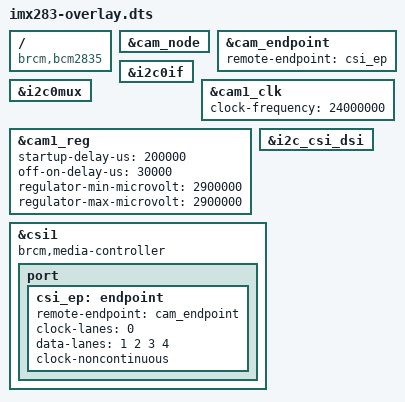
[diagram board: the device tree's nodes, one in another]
// SPDX-License-Identifier: GPL-2.0-only
// Definitions for IMX283 camera module on VC I2C bus
/dts-v1/;
/plugin/;

#include <dt-bindings/gpio/gpio.h>

/{
	compatible = "brcm,bcm2835";

	fragment@0 {
		target = <&i2c0if>;
		__overlay__ {
			status = "okay";
		};
	};

	clk_frag: fragment@1 {
		target = <&cam1_clk>;
		cam_clk: __overlay__ {
			status = "okay";
			clock-frequency = <24000000>;
		};
	};

	fragment@2 {
		target = <&i2c0mux>;
		__overlay__ {
			status = "okay";
		};
	};

	reg_frag: fragment@3 {
		target = <&cam1_reg>;
		cam_reg: __overlay__ {
			startup-delay-us = <200000>;
			off-on-delay-us = <30000>;
			regulator-min-microvolt = <2900000>;
			regulator-max-microvolt = <2900000>;
		};
	};

	i2c_frag: fragment@100 {
		target = <&i2c_csi_dsi>;
		__overlay__ {
			#address-cells = <1>;
			#size-cells = <0>;
			status = "okay";

			#include "imx283.dtsi"
		};
	};

	csi_frag: fragment@101 {
		target = <&csi1>;
		csi: __overlay__ {
			status = "okay";
			brcm,media-controller;

			port {
				csi_ep: endpoint {
					remote-endpoint = <&cam_endpoint>;
					clock-lanes = <0>;
					data-lanes = <1 2 3 4>;
					clock-noncontinuous;
				};
			};
		};
	};

	__overrides__ {
		clock-frequency = <&cam_clk>,"clock-frequency:0";
		rotation = <&cam_node>,"rotation:0";
		orientation = <&cam_node>,"orientation:0";
		media-controller = <&csi>,"brcm,media-controller?";
		cam0 = <&i2c_frag>, "target:0=",<&i2c_csi_dsi0>,
		       <&csi_frag>, "target:0=",<&csi0>,
		       <&clk_frag>, "target:0=",<&cam0_clk>,
		       <&reg_frag>, "target:0=",<&cam0_reg>,
		       <&cam_node>, "clocks:0=",<&cam0_clk>,
		       <&cam_node>, "vadd-supply:0=",<&cam0_reg>;
		link-frequency = <&cam_endpoint>,"link-frequencies#0";
	};
};

&cam_node {
	status = "okay";
};

&cam_endpoint {
	remote-endpoint = <&csi_ep>;
};
